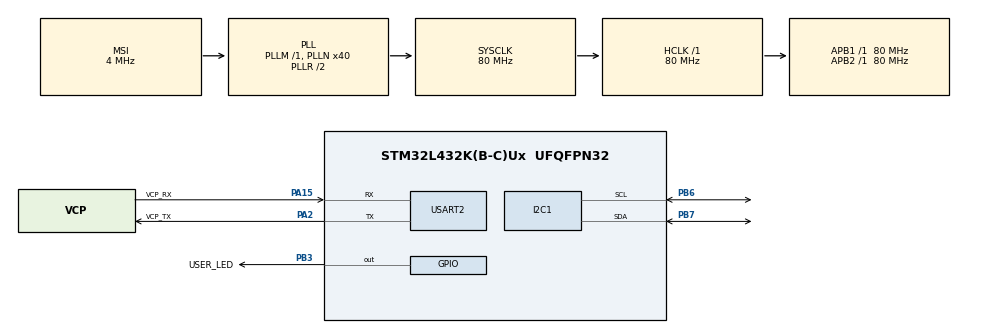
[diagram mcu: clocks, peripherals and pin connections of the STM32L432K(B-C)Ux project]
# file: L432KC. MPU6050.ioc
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I2C1.Timing=0x10D19CE4
Mcu.Family=STM32L4
Mcu.Name=STM32L432K(B-C)Ux
Mcu.Package=UFQFPN32
NVIC.PriorityGroup=NVIC_PRIORITYGROUP_4
PA0.GPIO_Label=MCO [High speed clock in]
PA0.Mode=HSE-External-Clock-Source-for-LittleOrca
PA0.Signal=RCC_CK_IN
PA13\ (JTMS-SWDIO).GPIO_Label=SWDIO
PA13\ (JTMS-SWDIO).Mode=Serial_Wire
PA13\ (JTMS-SWDIO).Signal=SYS_JTMS-SWDIO
PA14\ (JTCK-SWCLK).GPIO_Label=SWCLK
PA14\ (JTCK-SWCLK).Mode=Serial_Wire
PA14\ (JTCK-SWCLK).Signal=SYS_JTCK-SWCLK
PA15\ (JTDI).GPIO_Label=VCP_RX
PA15\ (JTDI).Mode=Asynchronous
PA15\ (JTDI).Signal=USART2_RX
PA2.GPIO_Label=VCP_TX
PA2.Mode=Asynchronous
PA2.Signal=USART2_TX
PB3\ (JTDO-TRACESWO).GPIO_Label=USER_LED
PB3\ (JTDO-TRACESWO).Signal=GPIO_Output
PB6.Mode=I2C
PB6.Signal=I2C1_SCL
PB7.Mode=I2C
PB7.Signal=I2C1_SDA
PC14-OSC32_IN\ (PC14).Mode=LSE-External-Oscillator
PC14-OSC32_IN\ (PC14).Signal=RCC_OSC32_IN
PC15-OSC32_OUT\ (PC15).Mode=LSE-External-Oscillator
PC15-OSC32_OUT\ (PC15).Signal=RCC_OSC32_OUT
ProjectManager.HeapSize=0x200
ProjectManager.StackSize=0x400
ProjectManager.TargetToolchain=STM32CubeIDE
RCC.AHBFreq_Value=80000000
RCC.APB1Freq_Value=80000000
RCC.APB1TimFreq_Value=80000000
RCC.APB2Freq_Value=80000000
RCC.APB2TimFreq_Value=80000000
RCC.CortexFreq_Value=80000000
RCC.HCLKFreq_Value=80000000
RCC.HSE_VALUE=8000000
RCC.HSI16_VALUE=16000000
RCC.HSI48_VALUE=48000000
RCC.HSI_VALUE=16000000
RCC.MSI_VALUE=4000000
RCC.PLLMUL=RCC_PLLMUL_4
RCC.PLLN=40
RCC.SYSCLKFreq_VALUE=80000000
RCC.SYSCLKSource=RCC_SYSCLKSOURCE_PLLCLK
RCC.VCOOutputFreq_Value=160000000
USART2.VirtualMode-Asynchronous=VM_ASYNC
board=NUCLEO-L432KC

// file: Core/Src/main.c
/* USER CODE BEGIN Header */
/**
  ******************************************************************************
  * @file           : main.c
  * @brief          : Main program body
  ******************************************************************************
  * @attention
  *
  * Copyright (c) 2026 STMicroelectronics.
  * All rights reserved.
  *
  * This software is licensed under terms that can be found in the LICENSE file
  * in the root directory of this software component.
  * If no LICENSE file comes with this software, it is provided AS-IS.
  *
  ******************************************************************************
  */
/* USER CODE END Header */
#include "main.h"

/* USER CODE BEGIN Includes */
#include <stdio.h>
#include <string.h>
#include "mpu6050.h"

/* USER CODE END Includes */

I2C_HandleTypeDef hi2c1;

UART_HandleTypeDef huart2;

/* USER CODE BEGIN PV */
MPU6050_t MPU6050_Data;
/* USER CODE END PV */

void SystemClock_Config(void);
static void MX_GPIO_Init(void);
static void MX_USART2_UART_Init(void);
static void MX_I2C1_Init(void);

/* USER CODE BEGIN 0 */

#include <stdio.h>

int _write(int file, char *ptr, int len)
{
	HAL_UART_Transmit(&huart2, (uint8_t*)ptr, len, HAL_MAX_DELAY);
	return len;
}

/* USER CODE END 0 */

int main(void)
{

  /* MCU Configuration--------------------------------------------------------*/

  /* Reset of all peripherals, Initializes the Flash interface and the Systick. */
  HAL_Init();
  SystemClock_Config();
  MX_GPIO_Init();
  MX_I2C1_Init();
  MX_USART2_UART_Init();

  /* Configure the system clock */
  SystemClock_Config();

  /* Initialize all configured peripherals */
  MX_GPIO_Init();
  MX_USART2_UART_Init();
  MX_I2C1_Init();
  /* USER CODE BEGIN 2 */

//  HAL_GPIO_WritePin(GPIOB, GPIO_PIN_3, GPIO_PIN_SET);
//
//  printf("STM32 L432KC Started!\r\n");

  printf("\r\n=== L432KC + MPU6050 Test ===\r\n");

  // MPU6050 초기화
  if(MPU6050_Init(&hi2c1)) {
      printf("MPU6050 Ready!\r\n\r\n");
  } else {
      printf("MPU6050 Init Failed!\r\n");
      Error_Handler();
  }

  /* USER CODE END 2 */

  /* Infinite loop */
  while (1)
  {
	  // 모든 센서 데이터 읽기
	  MPU6050_Read_All(&hi2c1, &MPU6050_Data);

	  // 출력 (가독성 좋게)
	  printf("Accel: X=%6.2f Y=%6.2f Z=%6.2f g | ", MPU6050_Data.Ax, MPU6050_Data.Ay, MPU6050_Data.Az);
	  printf("Gyro: X=%7.2f Y=%7.2f Z=%7.2f °/s\r\n",MPU6050_Data.Gx, MPU6050_Data.Gy, MPU6050_Data.Gz);

	  HAL_Delay(100);  // 10Hz 출력
  }
  /* USER CODE END 3 */
}

void SystemClock_Config(void)
{
  RCC_OscInitTypeDef RCC_OscInitStruct = {0};
  RCC_ClkInitTypeDef RCC_ClkInitStruct = {0};

  /** Configure the main internal regulator output voltage
  */
  if (HAL_PWREx_ControlVoltageScaling(PWR_REGULATOR_VOLTAGE_SCALE1) != HAL_OK)
  {
    Error_Handler();
  }

  /** Configure LSE Drive Capability
  */
  HAL_PWR_EnableBkUpAccess();
  __HAL_RCC_LSEDRIVE_CONFIG(RCC_LSEDRIVE_LOW);

  /** Initializes the RCC Oscillators according to the specified parameters
  * in the RCC_OscInitTypeDef structure.
  */
  RCC_OscInitStruct.OscillatorType = RCC_OSCILLATORTYPE_LSE|RCC_OSCILLATORTYPE_MSI;
  RCC_OscInitStruct.LSEState = RCC_LSE_ON;
  RCC_OscInitStruct.MSIState = RCC_MSI_ON;
  RCC_OscInitStruct.MSICalibrationValue = 0;
  RCC_OscInitStruct.MSIClockRange = RCC_MSIRANGE_6;
  RCC_OscInitStruct.PLL.PLLState = RCC_PLL_ON;
  RCC_OscInitStruct.PLL.PLLSource = RCC_PLLSOURCE_MSI;
  RCC_OscInitStruct.PLL.PLLM = 1;
  RCC_OscInitStruct.PLL.PLLN = 40;
  RCC_OscInitStruct.PLL.PLLP = RCC_PLLP_DIV7;
  RCC_OscInitStruct.PLL.PLLQ = RCC_PLLQ_DIV2;
  RCC_OscInitStruct.PLL.PLLR = RCC_PLLR_DIV2;
  if (HAL_RCC_OscConfig(&RCC_OscInitStruct) != HAL_OK)
  {
    Error_Handler();
  }

  /** Initializes the CPU, AHB and APB buses clocks
  */
  RCC_ClkInitStruct.ClockType = RCC_CLOCKTYPE_HCLK|RCC_CLOCKTYPE_SYSCLK
                              |RCC_CLOCKTYPE_PCLK1|RCC_CLOCKTYPE_PCLK2;
  RCC_ClkInitStruct.SYSCLKSource = RCC_SYSCLKSOURCE_PLLCLK;
  RCC_ClkInitStruct.AHBCLKDivider = RCC_SYSCLK_DIV1;
  RCC_ClkInitStruct.APB1CLKDivider = RCC_HCLK_DIV1;
  RCC_ClkInitStruct.APB2CLKDivider = RCC_HCLK_DIV1;

  if (HAL_RCC_ClockConfig(&RCC_ClkInitStruct, FLASH_LATENCY_4) != HAL_OK)
  {
    Error_Handler();
  }

  /** Enable MSI Auto calibration
  */
  HAL_RCCEx_EnableMSIPLLMode();
}

static void MX_I2C1_Init(void)
{

  hi2c1.Instance = I2C1;
  hi2c1.Init.Timing = 0x10D19CE4;
  hi2c1.Init.OwnAddress1 = 0;
  hi2c1.Init.AddressingMode = I2C_ADDRESSINGMODE_7BIT;
  hi2c1.Init.DualAddressMode = I2C_DUALADDRESS_DISABLE;
  hi2c1.Init.OwnAddress2 = 0;
  hi2c1.Init.OwnAddress2Masks = I2C_OA2_NOMASK;
  hi2c1.Init.GeneralCallMode = I2C_GENERALCALL_DISABLE;
  hi2c1.Init.NoStretchMode = I2C_NOSTRETCH_DISABLE;
  if (HAL_I2C_Init(&hi2c1) != HAL_OK)
  {
    Error_Handler();
  }

  /** Configure Analogue filter
  */
  if (HAL_I2CEx_ConfigAnalogFilter(&hi2c1, I2C_ANALOGFILTER_ENABLE) != HAL_OK)
  {
    Error_Handler();
  }

  /** Configure Digital filter
  */
  if (HAL_I2CEx_ConfigDigitalFilter(&hi2c1, 0) != HAL_OK)
  {
    Error_Handler();
  }

}

static void MX_USART2_UART_Init(void)
{

  huart2.Instance = USART2;
  huart2.Init.BaudRate = 115200;
  huart2.Init.WordLength = UART_WORDLENGTH_8B;
  huart2.Init.StopBits = UART_STOPBITS_1;
  huart2.Init.Parity = UART_PARITY_NONE;
  huart2.Init.Mode = UART_MODE_TX_RX;
  huart2.Init.HwFlowCtl = UART_HWCONTROL_NONE;
  huart2.Init.OverSampling = UART_OVERSAMPLING_16;
  huart2.Init.OneBitSampling = UART_ONE_BIT_SAMPLE_DISABLE;
  huart2.AdvancedInit.AdvFeatureInit = UART_ADVFEATURE_NO_INIT;
  if (HAL_UART_Init(&huart2) != HAL_OK)
  {
    Error_Handler();
  }

}

static void MX_GPIO_Init(void)
{
  GPIO_InitTypeDef GPIO_InitStruct = {0};

  /* GPIO Ports Clock Enable */
  __HAL_RCC_GPIOC_CLK_ENABLE();
  __HAL_RCC_GPIOA_CLK_ENABLE();
  __HAL_RCC_GPIOB_CLK_ENABLE();

  /*Configure GPIO pin Output Level */
  HAL_GPIO_WritePin(USER_LED_GPIO_Port, USER_LED_Pin, GPIO_PIN_RESET);

  /*Configure GPIO pin : USER_LED_Pin */
  GPIO_InitStruct.Pin = USER_LED_Pin;
  GPIO_InitStruct.Mode = GPIO_MODE_OUTPUT_PP;
  GPIO_InitStruct.Pull = GPIO_NOPULL;
  GPIO_InitStruct.Speed = GPIO_SPEED_FREQ_LOW;
  HAL_GPIO_Init(USER_LED_GPIO_Port, &GPIO_InitStruct);

}

void Error_Handler(void)
{
  __disable_irq();
  while (1)
  {
  }
}
